# DSS_CM register map
Vendor: Texas Instruments
Peripheral module from a debugger description file (folder omap36xx).
Registers are 32-bit, access per field, reset values left out (the file's numbers can be read two ways) unless marked. A register's access mark holds for its fields unless they carry their own. Offsets are as the file gives them; lines under a group give offsets from that group; [hi:lo] are bit positions; {n}, {i} and the like mark numbered series; 'fields as' and 'values as' point back to an identical list; <NAME> marks a mode.

## DSS_CM
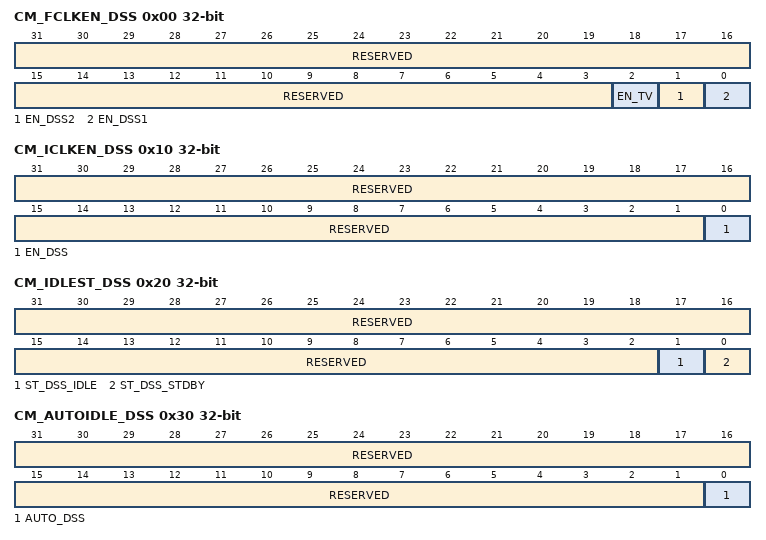
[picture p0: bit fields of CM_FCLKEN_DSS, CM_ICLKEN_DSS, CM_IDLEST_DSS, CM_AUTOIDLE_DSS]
0x00 CM_FCLKEN_DSS — Controls the modules functional clock activity.
  [31:3] RESERVED ro — Write 0s for future compatibility. Read returns 0.
  [2] EN_TV rw — DSS_TV_FCLK functional clock control
    0=DSS_TV_FCLK is disabled; 1=DSS_TV_FCLK is enabled
  [1] EN_DSS2 rw — Display Sub-System functional clock 2 control
    0=DSS2_ALWON_FCLK is disabled; 1=DSS2_ALWON_FCLK is enabled
  [0] EN_DSS1 rw — Display Sub-System functional clock 1 control
    0=DSS1_ALWON_FCLK is disabled; 1=DSS1_ALWON_FCLK is enabled
0x10 CM_ICLKEN_DSS — Controls the modules interface clock activity.
  [31:1] RESERVED ro — Write 0s for future compatibility. Read returns 0.
  [0] EN_DSS rw — Display sub-system interface clock control
    0=DSS_L3_ICLK and DSS_L4_ICLK are disabled; 1=DSS_L3_ICLK and DSS_L4_ICLK are enabled
0x20 CM_IDLEST_DSS ro — Modules access availability monitoring. This register is read only and automatically updated.
  [31:2] RESERVED — Read returns 0.
  [1] ST_DSS_IDLE — Display Sub-System idle status.
    0=Display Sub-System is active; 1=Display Sub-System is in idle mode and cannot be accessed
  [0] ST_DSS_STDBY — Display Sub-System standby status.
    0=Display Sub-System is active; 1=Display Sub-System is in standby mode
0x30 CM_AUTOIDLE_DSS — This register controls the automatic control of the modules interface clock activity.
  [31:1] RESERVED ro — Write 0s for future compatibility. Read returns 0.
  [0] AUTO_DSS rw — Display Sub-System auto clock control.
    0=Display Sub-System interface clock is unrelated to the domain state transition; 1=Display Sub-System interface clock is automatically enabled or disabled along with the domain state transition
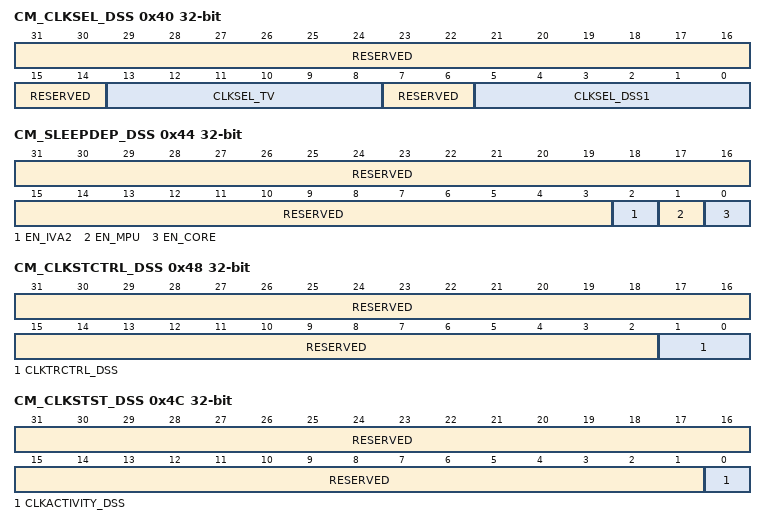
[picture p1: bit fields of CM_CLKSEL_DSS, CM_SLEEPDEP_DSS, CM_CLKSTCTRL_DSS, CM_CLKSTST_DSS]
0x40 CM_CLKSEL_DSS — Modules clock selection.
  [31:14] RESERVED ro — Write 0s for future compatibility. Read returns 0.
  [13:8] CLKSEL_TV rw — TV functional clock divider factor DPLL4 M3 (1 up to 32); Other enums: Reserved
    {v}=TV functional clock is DPLL4 clock divided by {v} (v=1..32)
  [7:6] RESERVED ro — Write 0s for future compatibility. Read returns 0.
  [5:0] CLKSEL_DSS1 rw — DPLL4 M4 divide factor for DSS1_ALWON_FCLK (1 up to 32); Other enums: Reserved
    {v}=DSS1_ALWON_FCLK is DPLL4 clock divided by {v} (v=1..32)
0x44 CM_SLEEPDEP_DSS — This register allows enabling or disabling the sleep transition dependency of DSS domain with respect to other domain.
  [31:3] RESERVED ro — Write 0s for future compatibility. Read returns 0.
  [2] EN_IVA2 rw — IVA2 domain dependency
    0=DSS domain sleep dependency with IVA2 domain is disabled; 1=DSS domain sleep dependency with IVA2 domain is enabled
  [1] EN_MPU rw — MPU domain dependency
    0=DSS domain sleep dependency with MPU domain is disabled; 1=DSS domain sleep dependency with MPU domain is enabled
  [0] EN_CORE rw — CORE domain dependency
    0=DSS domain sleep dependency with CORE domain is disabled; 1=DSS domain sleep dependency with CORE domain is enabled
0x48 CM_CLKSTCTRL_DSS — This register enables the domain power state transition. It controls the HW supervised domain power state transition between ACTIVE and INACTIVE states.
  [31:2] RESERVED ro — Write 0s for future compatibility. Read returns 0.
  [1:0] CLKTRCTRL_DSS rw — Controls the clock state transition of the DSS clock domain.
    0=Automatic transition is disabled; 1=Start a software supervised sleep transition on the domain; 2=Start a software supervised wake-up transition on the domain; 3=Automatic transition is enabled. Transition is supervised by the HardWare.
0x4C CM_CLKSTST_DSS ro — This register provides a status on the OCP interface clock activity in the domain.
  [31:1] RESERVED — Write 0s for future compatibility. Read returns 0.
  [0] CLKACTIVITY_DSS — Interface clock activity status
    0=No domain Interface clock activity; 1=Domain Interface clock is active
